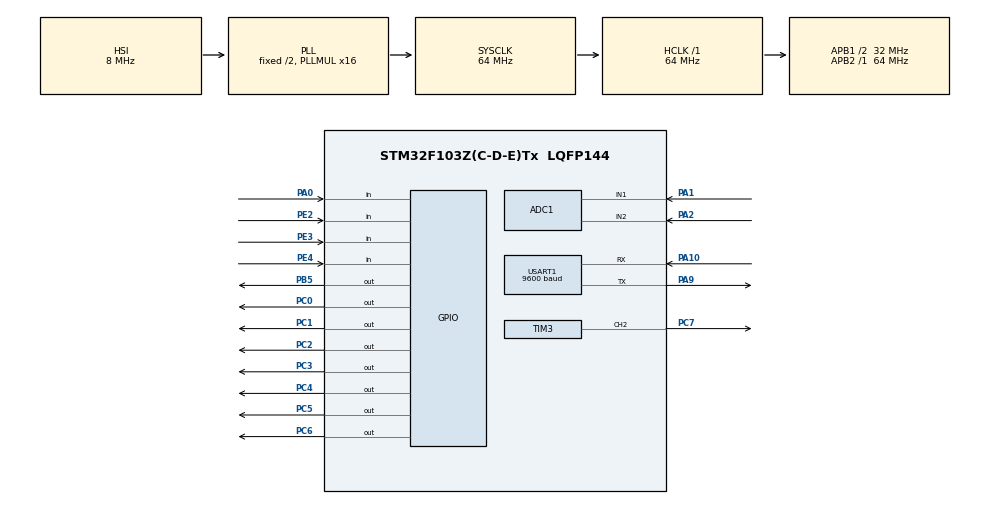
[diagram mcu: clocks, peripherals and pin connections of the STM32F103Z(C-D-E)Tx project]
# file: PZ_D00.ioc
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ADC1.Channel-19\#ChannelRegularConversion=ADC_CHANNEL_1
ADC1.Channel-20\#ChannelRegularConversion=ADC_CHANNEL_2
ADC1.ContinuousConvMode=DISABLE
ADC1.DataAlign=ADC_DATAALIGN_RIGHT
ADC1.DiscontinuousConvMode=DISABLE
ADC1.EnableAnalogWatchDog=false
ADC1.EnableRegularConversion=ENABLE
ADC1.ExternalTrigConv=ADC_EXTERNALTRIGCONV_T3_TRGO
ADC1.InjNumberOfConversion=0
ADC1.NbrOfConversion=2
ADC1.NbrOfConversionFlag=1
ADC1.Rank-19\#ChannelRegularConversion=1
ADC1.Rank-20\#ChannelRegularConversion=2
ADC1.SamplingTime-19\#ChannelRegularConversion=ADC_SAMPLETIME_13CYCLES_5
ADC1.SamplingTime-20\#ChannelRegularConversion=ADC_SAMPLETIME_13CYCLES_5
ADC1.ScanConvMode=ADC_SCAN_ENABLE
ADC1.master=1
Dma.ADC1.0.Direction=DMA_PERIPH_TO_MEMORY
Dma.ADC1.0.Instance=DMA1_Channel1
Dma.ADC1.0.MemDataAlignment=DMA_MDATAALIGN_HALFWORD
Dma.ADC1.0.MemInc=DMA_MINC_ENABLE
Dma.ADC1.0.Mode=DMA_CIRCULAR
Dma.ADC1.0.PeriphDataAlignment=DMA_PDATAALIGN_HALFWORD
Dma.ADC1.0.PeriphInc=DMA_PINC_DISABLE
Dma.ADC1.0.Priority=DMA_PRIORITY_LOW
Dma.Request0=ADC1
Mcu.Family=STM32F1
Mcu.Name=STM32F103Z(C-D-E)Tx
Mcu.Package=LQFP144
NVIC.DMA1_Channel1_IRQn=true\:0\:0\:false\:false\:true\:false\:true
NVIC.PriorityGroup=NVIC_PRIORITYGROUP_4
NVIC.TIM3_IRQn=true\:0\:0\:false\:false\:true\:true\:true
NVIC.USART1_IRQn=true\:1\:0\:true\:false\:true\:true\:true
PA0-WKUP.GPIO_PuPd=GPIO_PULLDOWN
PA0-WKUP.Signal=GPIO_Input
PA1.Signal=ADCx_IN1
PA10.Mode=Asynchronous
PA10.Signal=USART1_RX
PA13.Mode=Serial_Wire
PA13.Signal=SYS_JTMS-SWDIO
PA14.Mode=Serial_Wire
PA14.Signal=SYS_JTCK-SWCLK
PA2.Signal=ADCx_IN2
PA9.Mode=Asynchronous
PA9.Signal=USART1_TX
PB5.GPIO_PuPd=GPIO_PULLUP
PB5.PinState=GPIO_PIN_SET
PB5.Signal=GPIO_Output
PC0.Signal=GPIO_Output
PC1.Signal=GPIO_Output
PC2.Signal=GPIO_Output
PC3.Signal=GPIO_Output
PC4.Signal=GPIO_Output
PC5.Signal=GPIO_Output
PC6.Signal=GPIO_Output
PC7.Signal=S_TIM3_CH2
PE2.GPIO_PuPd=GPIO_PULLUP
PE2.Signal=GPIO_Input
PE3.GPIO_PuPd=GPIO_PULLUP
PE3.Signal=GPIO_Input
PE4.GPIO_PuPd=GPIO_PULLUP
PE4.Signal=GPIO_Input
ProjectManager.HeapSize=0x200
ProjectManager.StackSize=0x400
ProjectManager.TargetToolchain=MDK-ARM V5
RCC.ADCPresc=RCC_ADCPCLK2_DIV8
RCC.AHBFreq_Value=64000000
RCC.APB1CLKDivider=RCC_HCLK_DIV2
RCC.APB1Freq_Value=32000000
RCC.APB1TimFreq_Value=64000000
RCC.APB2Freq_Value=64000000
RCC.APB2TimFreq_Value=64000000
RCC.HCLKFreq_Value=64000000
RCC.PLLMUL=RCC_PLL_MUL16
RCC.SYSCLKFreq_VALUE=64000000
RCC.SYSCLKSource=RCC_SYSCLKSOURCE_PLLCLK
RCC.USBFreq_Value=64000000
RTC.Format=RTC_FORMAT_BIN
RTC.OutPut=RTC_OUTPUTSOURCE_CALIBCLOCK
SH.ADCx_IN1.0=ADC1_IN1,IN1
SH.ADCx_IN2.0=ADC1_IN2,IN2
SH.S_TIM3_CH2.0=TIM3_CH2,PWM Generation2 CH2
TIM3.AutoReloadPreload=TIM_AUTORELOAD_PRELOAD_ENABLE
TIM3.Channel-PWM\ Generation2\ CH2=TIM_CHANNEL_2
TIM3.Period=2499
TIM3.Prescaler=7
TIM3.Pulse-PWM\ Generation2\ CH2=6
TIM3.TIM_MasterOutputTrigger=TIM_TRGO_OC1
USART1.BaudRate=9600
USART1.Parity=PARITY_NONE
USART1.VirtualMode=VM_ASYNC
USART1.WordLength=WORDLENGTH_8B
VP_RTC_VS_RTC_Activate.Mode=RTC_Enabled
VP_TIM3_VS_ClockSourceINT.Mode=Internal
board=PZ_D00

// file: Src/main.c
/* USER CODE BEGIN Header */
/**
  ******************************************************************************
  * @file           : main.c
  * @brief          : Main program body
  ******************************************************************************
  * @attention
  *
  * <h2><center>&copy; Copyright (c) 2020 STMicroelectronics.
  * All rights reserved.</center></h2>
  *
  * This software component is licensed by ST under BSD 3-Clause license,
  * the "License"; You may not use this file except in compliance with the
  * License. You may obtain a copy of the License at:
  *                        opensource.org/licenses/BSD-3-Clause
  *
  ******************************************************************************
  */
/* USER CODE END Header */

#include "main.h"

ADC_HandleTypeDef hadc1;
DMA_HandleTypeDef hdma_adc1;

RTC_HandleTypeDef hrtc;

TIM_HandleTypeDef htim3;

UART_HandleTypeDef huart1;

void SystemClock_Config(void);
static void MX_GPIO_Init(void);
static void MX_DMA_Init(void);
static void MX_ADC1_Init(void);
static void MX_TIM3_Init(void);
static void MX_USART1_UART_Init(void);
static void MX_RTC_Init(void);
/* USER CODE BEGIN PFP */
//---此程序仅供参考，不提供更多解释。有疑问请查阅资料。进一步内容及设计需自行解决。
struct  staCOMPONENT
{	short		sBUF[16],ADdat[16],	UART_rBUF[8],	mDMA[8],
				mRTC,		Cnt00,		Cnt01,			Cnt02;}md;	//该数据做程序处理、观察的主要方面
/* USER CODE END PFP */

/* USER CODE BEGIN 0       该部分内容可自由修改*/
const char LEDcd[10]={0xc0,0xf9,0xa4,0xb0,0x99,0x92,0x82,0xf8,0x80,0x90};
short xuehao[10]={2,1,8,6,1,1,3,5,6,4};
short i=0,x=3,*epmd;
void Delay(unsigned tDly)
{	short tDi;
	while(tDly--)
	{	tDi=4000;
		while(tDi--)
		{	if(!(md.mDMA[6]&0x10))	continue;
			     md.mDMA[6]&=~0x10;		md.mDMA[5]++;
																	//can do some works, but no stay here more time
		}
//自行扩展Begin......u can do something
		md.mRTC=RTC->CNTL;

//自行扩展END  ......u can do something
	};
}
//---------????---------------------------------------------------
void HAL_UART_RxCpltCallback(UART_HandleTypeDef *huart)
{	md.mDMA[2]++;	md.mDMA[2]&=0x7;
	md.UART_rBUF[md.mDMA[2]]=md.mDMA[3];
	HAL_UART_Receive_IT(&huart1,(unsigned char *)&md.mDMA[3],1);	//	USART1->DR=md.mDMA[3]+1;
	if(md.mDMA[3]==0x11)
	{
		for(int i=0;i<10;i++)
		{
			HAL_UART_Transmit(&huart1,(unsigned char *)&md.sBUF[i],1,5000);
		}
	}
	else
	{
		md.mDMA[4]=md.mDMA[3]+1;

		while(HAL_UART_Transmit(&huart1,(unsigned char *)&md.mDMA[4],1,5000)!=HAL_OK);
	}

}
/* USER CODE END 0 */

int main(void)
{

  /* MCU Configuration--------------------------------------------------------*/

  /* Reset of all peripherals, Initializes the Flash interface and the Systick. */
  HAL_Init();

  /* Configure the system clock */
  SystemClock_Config();

  /* Initialize all configured peripherals */
  MX_GPIO_Init();
  MX_DMA_Init();
  MX_ADC1_Init();
  MX_TIM3_Init();
  MX_USART1_UART_Init();
  MX_RTC_Init();
  /* USER CODE BEGIN 2 该部分内容不做更多解释*/
	TIM3->CCER|=1<<4;	HAL_TIM_Base_Start_IT(&htim3);					//TIM3->CR1|=1;	TIM3->DIER|=4;
	HAL_ADCEx_Calibration_Start(&hadc1);									//step1
	HAL_ADC_Start_DMA(&hadc1,(unsigned int *)md.mDMA,2);				//step1
	HAL_UART_Receive_IT(&huart1,(unsigned char *)&md.mDMA[3],1);	//step1
	epmd=(short *)&md;
  /* USER CODE END 2 */

  /* Infinite loop */
  /* USER CODE BEGIN WHILE */
  while (1)
  {
    /* USER CODE END WHILE 该部分内容可自由修改*/
		if(!(GPIOA->IDR&1))	i++; 	else
		{	i+=9;						}											//T1_5:	有UP键按下(PA0 is 1)
		GPIOC->BSRR|=LEDcd[xuehao[i%=10]]&0xff;									//T1_1:	LED显示(PC7-0)
		Delay(500+i*23);			GPIOC->BRR|=0xff;						//T1_2:	延迟， 0.5s+学号个位数*0.1s
//------------------------------------
		md.sBUF[i]=xuehao[i];														//T1_3:	填充学号各位至sBUF[0--x]
		if(i==0)	{	md.sBUF[14]=md.sBUF[15];	md.sBUF[15]=0;}
		md.sBUF[15]+=md.sBUF[i];											//T1_4:	累加sBUF[x]，最终累加和存至sBUF[14]
//自行扩展Begin

//自行扩展END
  }
}

void SystemClock_Config(void)
{
  RCC_OscInitTypeDef RCC_OscInitStruct = {0};
  RCC_ClkInitTypeDef RCC_ClkInitStruct = {0};
  RCC_PeriphCLKInitTypeDef PeriphClkInit = {0};

  /** Initializes the CPU, AHB and APB busses clocks
  */
  RCC_OscInitStruct.OscillatorType = RCC_OSCILLATORTYPE_HSI|RCC_OSCILLATORTYPE_LSI;
  RCC_OscInitStruct.HSIState = RCC_HSI_ON;
  RCC_OscInitStruct.HSICalibrationValue = RCC_HSICALIBRATION_DEFAULT;
  RCC_OscInitStruct.LSIState = RCC_LSI_ON;
  RCC_OscInitStruct.PLL.PLLState = RCC_PLL_ON;
  RCC_OscInitStruct.PLL.PLLSource = RCC_PLLSOURCE_HSI_DIV2;
  RCC_OscInitStruct.PLL.PLLMUL = RCC_PLL_MUL16;
  if (HAL_RCC_OscConfig(&RCC_OscInitStruct) != HAL_OK)
  {
    Error_Handler();
  }
  /** Initializes the CPU, AHB and APB busses clocks
  */
  RCC_ClkInitStruct.ClockType = RCC_CLOCKTYPE_HCLK|RCC_CLOCKTYPE_SYSCLK
                              |RCC_CLOCKTYPE_PCLK1|RCC_CLOCKTYPE_PCLK2;
  RCC_ClkInitStruct.SYSCLKSource = RCC_SYSCLKSOURCE_PLLCLK;
  RCC_ClkInitStruct.AHBCLKDivider = RCC_SYSCLK_DIV1;
  RCC_ClkInitStruct.APB1CLKDivider = RCC_HCLK_DIV2;
  RCC_ClkInitStruct.APB2CLKDivider = RCC_HCLK_DIV1;

  if (HAL_RCC_ClockConfig(&RCC_ClkInitStruct, FLASH_LATENCY_2) != HAL_OK)
  {
    Error_Handler();
  }
  PeriphClkInit.PeriphClockSelection = RCC_PERIPHCLK_RTC|RCC_PERIPHCLK_ADC;
  PeriphClkInit.RTCClockSelection = RCC_RTCCLKSOURCE_LSI;
  PeriphClkInit.AdcClockSelection = RCC_ADCPCLK2_DIV8;
  if (HAL_RCCEx_PeriphCLKConfig(&PeriphClkInit) != HAL_OK)
  {
    Error_Handler();
  }
}

static void MX_ADC1_Init(void)
{

  ADC_ChannelConfTypeDef sConfig = {0};

  /** Common config
  */
  hadc1.Instance = ADC1;
  hadc1.Init.ScanConvMode = ADC_SCAN_ENABLE;
  hadc1.Init.ContinuousConvMode = DISABLE;
  hadc1.Init.DiscontinuousConvMode = DISABLE;
  hadc1.Init.ExternalTrigConv = ADC_EXTERNALTRIGCONV_T3_TRGO;
  hadc1.Init.DataAlign = ADC_DATAALIGN_RIGHT;
  hadc1.Init.NbrOfConversion = 2;
  if (HAL_ADC_Init(&hadc1) != HAL_OK)
  {
    Error_Handler();
  }
  /** Configure Regular Channel
  */
  sConfig.Channel = ADC_CHANNEL_1;
  sConfig.Rank = ADC_REGULAR_RANK_1;
  sConfig.SamplingTime = ADC_SAMPLETIME_13CYCLES_5;
  if (HAL_ADC_ConfigChannel(&hadc1, &sConfig) != HAL_OK)
  {
    Error_Handler();
  }
  /** Configure Regular Channel
  */
  sConfig.Channel = ADC_CHANNEL_2;
  sConfig.Rank = ADC_REGULAR_RANK_2;
  if (HAL_ADC_ConfigChannel(&hadc1, &sConfig) != HAL_OK)
  {
    Error_Handler();
  }

}

static void MX_RTC_Init(void)
{

  /** Initialize RTC Only
  */
  hrtc.Instance = RTC;
  hrtc.Init.AsynchPrediv = RTC_AUTO_1_SECOND;
  hrtc.Init.OutPut = RTC_OUTPUTSOURCE_CALIBCLOCK;
  if (HAL_RTC_Init(&hrtc) != HAL_OK)
  {
    Error_Handler();
  }

}

static void MX_TIM3_Init(void)
{

  TIM_ClockConfigTypeDef sClockSourceConfig = {0};
  TIM_MasterConfigTypeDef sMasterConfig = {0};
  TIM_OC_InitTypeDef sConfigOC = {0};

  htim3.Instance = TIM3;
  htim3.Init.Prescaler = 7;
  htim3.Init.CounterMode = TIM_COUNTERMODE_UP;
  htim3.Init.Period = 2499+6;									//学号个位
  htim3.Init.ClockDivision = TIM_CLOCKDIVISION_DIV1;
  htim3.Init.AutoReloadPreload = TIM_AUTORELOAD_PRELOAD_ENABLE;
  if (HAL_TIM_Base_Init(&htim3) != HAL_OK)
  {
    Error_Handler();
  }
  sClockSourceConfig.ClockSource = TIM_CLOCKSOURCE_INTERNAL;
  if (HAL_TIM_ConfigClockSource(&htim3, &sClockSourceConfig) != HAL_OK)
  {
    Error_Handler();
  }
  if (HAL_TIM_PWM_Init(&htim3) != HAL_OK)
  {
    Error_Handler();
  }
  sMasterConfig.MasterOutputTrigger = TIM_TRGO_OC1;
  sMasterConfig.MasterSlaveMode = TIM_MASTERSLAVEMODE_DISABLE;
  if (HAL_TIMEx_MasterConfigSynchronization(&htim3, &sMasterConfig) != HAL_OK)
  {
    Error_Handler();
  }
  sConfigOC.OCMode = TIM_OCMODE_PWM1;
  sConfigOC.Pulse = 6;
  sConfigOC.OCPolarity = TIM_OCPOLARITY_HIGH;
  sConfigOC.OCFastMode = TIM_OCFAST_DISABLE;
  if (HAL_TIM_PWM_ConfigChannel(&htim3, &sConfigOC, TIM_CHANNEL_2) != HAL_OK)
  {
    Error_Handler();
  }
  HAL_TIM_MspPostInit(&htim3);

}

static void MX_USART1_UART_Init(void)
{

  huart1.Instance = USART1;
  huart1.Init.BaudRate = 9600;
  huart1.Init.WordLength = UART_WORDLENGTH_8B;
  huart1.Init.StopBits = UART_STOPBITS_1;
  huart1.Init.Parity = UART_PARITY_NONE;
  huart1.Init.Mode = UART_MODE_TX_RX;
  huart1.Init.HwFlowCtl = UART_HWCONTROL_NONE;
  huart1.Init.OverSampling = UART_OVERSAMPLING_16;
  if (HAL_UART_Init(&huart1) != HAL_OK)
  {
    Error_Handler();
  }

}

static void MX_DMA_Init(void)
{

  /* DMA controller clock enable */
  __HAL_RCC_DMA1_CLK_ENABLE();

  /* DMA interrupt init */
  /* DMA1_Channel1_IRQn interrupt configuration */
  HAL_NVIC_SetPriority(DMA1_Channel1_IRQn, 0, 0);
  HAL_NVIC_EnableIRQ(DMA1_Channel1_IRQn);

}

static void MX_GPIO_Init(void)
{
  GPIO_InitTypeDef GPIO_InitStruct = {0};

  /* GPIO Ports Clock Enable */
  __HAL_RCC_GPIOE_CLK_ENABLE();
  __HAL_RCC_GPIOC_CLK_ENABLE();
  __HAL_RCC_GPIOA_CLK_ENABLE();
  __HAL_RCC_GPIOB_CLK_ENABLE();

  /*Configure GPIO pin Output Level */
  HAL_GPIO_WritePin(GPIOC, GPIO_PIN_0|GPIO_PIN_1|GPIO_PIN_2|GPIO_PIN_3
                          |GPIO_PIN_4|GPIO_PIN_5|GPIO_PIN_6, GPIO_PIN_RESET);

  /*Configure GPIO pin Output Level */
  HAL_GPIO_WritePin(GPIOB, GPIO_PIN_5, GPIO_PIN_SET);

  /*Configure GPIO pins : PE2 PE3 PE4 */
  GPIO_InitStruct.Pin = GPIO_PIN_2|GPIO_PIN_3|GPIO_PIN_4;
  GPIO_InitStruct.Mode = GPIO_MODE_INPUT;
  GPIO_InitStruct.Pull = GPIO_PULLUP;
  HAL_GPIO_Init(GPIOE, &GPIO_InitStruct);

  /*Configure GPIO pins : PC0 PC1 PC2 PC3
                           PC4 PC5 PC6 */
  GPIO_InitStruct.Pin = GPIO_PIN_0|GPIO_PIN_1|GPIO_PIN_2|GPIO_PIN_3
                          |GPIO_PIN_4|GPIO_PIN_5|GPIO_PIN_6;
  GPIO_InitStruct.Mode = GPIO_MODE_OUTPUT_PP;
  GPIO_InitStruct.Pull = GPIO_NOPULL;
  GPIO_InitStruct.Speed = GPIO_SPEED_FREQ_LOW;
  HAL_GPIO_Init(GPIOC, &GPIO_InitStruct);

  /*Configure GPIO pin : PA0 */
  GPIO_InitStruct.Pin = GPIO_PIN_0;
  GPIO_InitStruct.Mode = GPIO_MODE_INPUT;
  GPIO_InitStruct.Pull = GPIO_PULLDOWN;
  HAL_GPIO_Init(GPIOA, &GPIO_InitStruct);

  /*Configure GPIO pin : PB5 */
  GPIO_InitStruct.Pin = GPIO_PIN_5;
  GPIO_InitStruct.Mode = GPIO_MODE_OUTPUT_PP;
  GPIO_InitStruct.Pull = GPIO_PULLUP;
  GPIO_InitStruct.Speed = GPIO_SPEED_FREQ_LOW;
  HAL_GPIO_Init(GPIOB, &GPIO_InitStruct);

}

void Error_Handler(void)
{
}

/************************ (C) COPYRIGHT STMicroelectronics *****END OF FILE****/
